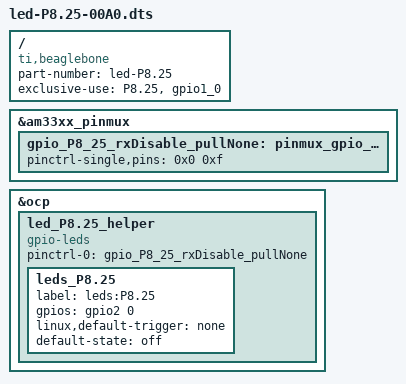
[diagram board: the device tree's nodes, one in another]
/*
* Easy gpio mux control of "P8.25" ("gpio1_0")
*/
/dts-v1/;
/plugin/;

/ {
	compatible = "ti,beaglebone", "ti,beaglebone-black";

	/* identification */
	part-number = "led-P8.25";
	/* version = "00A0"; */

	/* state the resources this cape uses */
	exclusive-use =
		/* the pin header uses */
		"P8.25",

		/* the hardware IP uses */
		"gpio1_0";
	
	
	/* rxDisable_pullNone state */
	fragment@0 {
		target = <&am33xx_pinmux>;
		__overlay__ {
			gpio_P8_25_rxDisable_pullNone: pinmux_gpio_P8.25_rxDisable_pullNone {
				pinctrl-single,pins = <
					0x0 0xf
				>;
			};
		};
	};

	fragment@1 {
		target = <&ocp>;
		__overlay__ {
			led_P8.25_helper {
				compatible = "gpio-leds";
				pinctrl-names = "default";
				pinctrl-0 = <&gpio_P8_25_rxDisable_pullNone>;
				
				leds_P8.25 {
					label = "leds:P8.25";
					gpios = <&gpio2 0 0>;
					linux,default-trigger = "none";
					default-state = "off";
				};
			};
			
		};
	};

};
